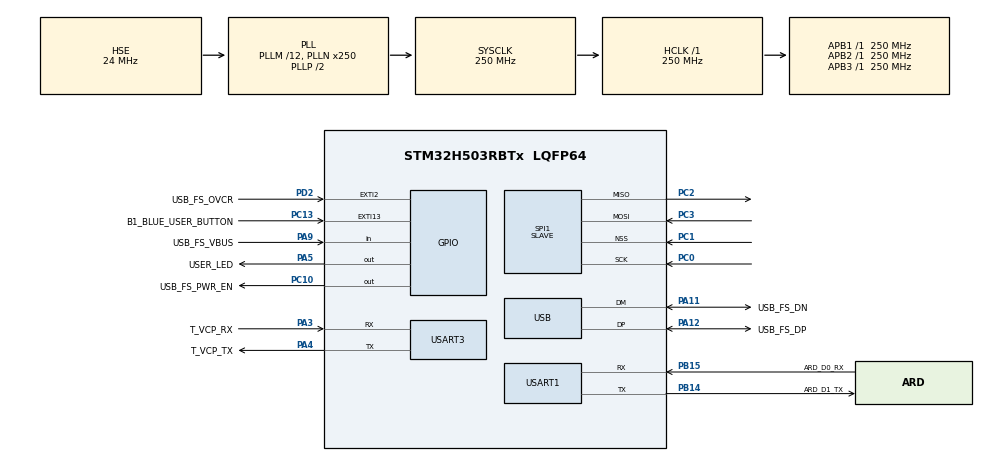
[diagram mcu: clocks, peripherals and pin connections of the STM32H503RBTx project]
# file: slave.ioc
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Mcu.Family=STM32H5
Mcu.Name=STM32H503RBTx
Mcu.Package=LQFP64
NVIC.PriorityGroup=NVIC_PRIORITYGROUP_4
PA11.GPIO_Label=USB_FS_DN
PA11.Mode=Device
PA11.Signal=USB_DM
PA12.GPIO_Label=USB_FS_DP
PA12.Mode=Device
PA12.Signal=USB_DP
PA13(JTMS/SWDIO).GPIO_Label=T_SWDIO
PA13(JTMS/SWDIO).Mode=JTAG_4_pins
PA13(JTMS/SWDIO).Signal=DEBUG_JTMS-SWDIO
PA14(JTCK/SWCLK).GPIO_Label=T_SWCLK
PA14(JTCK/SWCLK).Mode=JTAG_4_pins
PA14(JTCK/SWCLK).Signal=DEBUG_JTCK-SWCLK
PA15(JTDI).GPIO_Label=T_JTDI
PA15(JTDI).Mode=JTAG_4_pins
PA15(JTDI).Signal=DEBUG_JTDI
PA3.GPIO_Label=T_VCP_RX
PA3.Mode=Asynchronous
PA3.Signal=USART3_RX
PA4.GPIO_Label=T_VCP_TX
PA4.Mode=Asynchronous
PA4.Signal=USART3_TX
PA5.GPIO_Label=USER_LED
PA5.Signal=GPIO_Output
PA9.GPIO_Label=USB_FS_VBUS
PA9.Signal=GPIO_Input
PB14.GPIO_Label=ARD_D1_TX
PB14.Mode=Asynchronous
PB14.Signal=USART1_TX
PB15.GPIO_Label=ARD_D0_RX
PB15.Mode=Asynchronous
PB15.Signal=USART1_RX
PB3(JTDO/TRACESWO).GPIO_Label=T_SWO
PB3(JTDO/TRACESWO).Mode=JTAG_4_pins
PB3(JTDO/TRACESWO).Signal=DEBUG_JTDO-SWO
PC0.Mode=Full_Duplex_Slave
PC0.Signal=SPI1_SCK
PC1.Mode=NSS_Signal_Hard_Input
PC1.Signal=SPI1_NSS
PC10.GPIO_Label=USB_FS_PWR_EN
PC10.Signal=GPIO_Output
PC13.GPIO_Label=B1_BLUE_USER_BUTTON
PC13.Signal=GPXTI13
PC14-OSC32_IN(OSC32_IN).Mode=LSE-External-Oscillator
PC14-OSC32_IN(OSC32_IN).Signal=RCC_OSC32_IN
PC15-OSC32_OUT(OSC32_OUT).Mode=LSE-External-Oscillator
PC15-OSC32_OUT(OSC32_OUT).Signal=RCC_OSC32_OUT
PC2.Mode=Full_Duplex_Slave
PC2.Signal=SPI1_MISO
PC3.Mode=Full_Duplex_Slave
PC3.Signal=SPI1_MOSI
PD2.GPIO_Label=USB_FS_OVCR
PD2.Signal=GPXTI2
PH0-OSC_IN(PH0).Mode=HSE-External-Oscillator
PH0-OSC_IN(PH0).Signal=RCC_OSC_IN
PH1-OSC_OUT(PH1).Mode=HSE-External-Oscillator
PH1-OSC_OUT(PH1).Signal=RCC_OSC_OUT
ProjectManager.HeapSize=0x200
ProjectManager.StackSize=0x400
ProjectManager.TargetToolchain=STM32CubeIDE
RCC.ADCFreq_Value=250000000
RCC.AHBFreq_Value=250000000
RCC.APB1Freq_Value=250000000
RCC.APB1TimFreq_Value=250000000
RCC.APB2Freq_Value=250000000
RCC.APB2TimFreq_Value=250000000
RCC.APB3Freq_Value=250000000
RCC.CSI_VALUE=4000000
RCC.CortexFreq_Value=250000000
RCC.EPOD_VALUE=24000000
RCC.HCLKFreq_Value=250000000
RCC.HSE_VALUE=24000000
RCC.HSI48_VALUE=48000000
RCC.HSIDiv=RCC_HSI_DIV1
RCC.HSI_VALUE=64000000
RCC.LSIRC_VALUE=32000
RCC.PLLM=12
RCC.PLLN=250
RCC.PLLSourceVirtual=RCC_PLL1_SOURCE_HSE
RCC.SYSCLKFreq_VALUE=250000000
RCC.SYSCLKSource=RCC_SYSCLKSOURCE_PLLCLK
RCC.USBFreq_Value=48000000
RCC.VCOOutputFreq_Value=500000000
SPI1.DataSize=SPI_DATASIZE_8BIT
SPI1.Direction=SPI_DIRECTION_2LINES
SPI1.Mode=SPI_MODE_SLAVE
SPI1.VirtualNSS=VM_NSSHARD
SPI1.VirtualType=VM_SLAVE
USART1.VirtualMode=VM_ASYNC
USART3.VirtualMode=VM_ASYNC
USB.VirtualMode=Device_Only
VP_BOOTPATH_VS_BOOTPATH.Mode=BP_Activate
VP_ICACHE_VS_ICACHE.Mode=DefaultMode
VP_MEMORYMAP_VS_MEMORYMAP.Mode=CurAppReg
VP_PWR_VS_DBSignals.Mode=DisableDeadBatterySignals
VP_PWR_VS_LPOM.Mode=PowerOptimisation
VP_PWR_VS_SECSignals.Mode=Security/Privilege
board=NUCLEO-H503RB

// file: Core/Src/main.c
/* USER CODE BEGIN Header */
/**
  ******************************************************************************
  * @file           : main.c
  * @brief          : Main program body
  ******************************************************************************
  * @attention
  *
  * Copyright (c) 2024 STMicroelectronics.
  * All rights reserved.
  *
  * This software is licensed under terms that can be found in the LICENSE file
  * in the root directory of this software component.
  * If no LICENSE file comes with this software, it is provided AS-IS.
  *
  ******************************************************************************
  */
/* USER CODE END Header */
#include "main.h"

SPI_HandleTypeDef hspi1;

UART_HandleTypeDef huart1;
UART_HandleTypeDef huart3;

PCD_HandleTypeDef hpcd_USB_DRD_FS;

void SystemClock_Config(void);
static void MX_GPIO_Init(void);
static void MX_ICACHE_Init(void);
static void MX_USART1_UART_Init(void);
static void MX_USART3_UART_Init(void);
static void MX_USB_PCD_Init(void);
static void MX_SPI1_Init(void);

int main(void)
{
  /* USER CODE BEGIN 1 */

	uint8_t expected_data = 0xAA;
	  uint8_t received_data;

  /* USER CODE END 1 */

  /* MCU Configuration--------------------------------------------------------*/

  /* Reset of all peripherals, Initializes the Flash interface and the Systick. */
  HAL_Init();

  /* Configure the system clock */
  SystemClock_Config();

  /* Initialize all configured peripherals */
  MX_GPIO_Init();
  MX_ICACHE_Init();
  MX_USART1_UART_Init();
  MX_USART3_UART_Init();
  MX_USB_PCD_Init();
  MX_SPI1_Init();

  /* Infinite loop */
  /* USER CODE BEGIN WHILE */
	while (1) {

		if (HAL_SPI_Receive(&hspi1, &received_data, 1, HAL_MAX_DELAY)
				== HAL_OK) {
			// Check if received data matches the expected data
			if (received_data == expected_data) {
				for (int i = 0; i < 5; i++) {
					HAL_GPIO_TogglePin(USER_LED_GPIO_Port, USER_LED_Pin);
					HAL_Delay(1000);
				}
				// Data received correctly
				// Add your logic here (e.g., toggle an LED or perform other actions)
				// Example: HAL_GPIO_TogglePin(GPIOB, GPIO_PIN_13); // Toggle LED on GPIOB pin 13
			} else {

				HAL_GPIO_WritePin(USER_LED_GPIO_Port, USER_LED_Pin,
						GPIO_PIN_RESET);
				// Data received incorrectly
				// Add error handling or debugging code here
			}
		}

		HAL_Delay(100); // Adjust delay based on communication frequency
    /* USER CODE END WHILE */

	}
}

void SystemClock_Config(void)
{
  RCC_OscInitTypeDef RCC_OscInitStruct = {0};
  RCC_ClkInitTypeDef RCC_ClkInitStruct = {0};

  /** Configure the main internal regulator output voltage
  */
  __HAL_PWR_VOLTAGESCALING_CONFIG(PWR_REGULATOR_VOLTAGE_SCALE0);

  while(!__HAL_PWR_GET_FLAG(PWR_FLAG_VOSRDY)) {}

  /** Initializes the RCC Oscillators according to the specified parameters
  * in the RCC_OscInitTypeDef structure.
  */
  RCC_OscInitStruct.OscillatorType = RCC_OSCILLATORTYPE_HSI48|RCC_OSCILLATORTYPE_HSE;
  RCC_OscInitStruct.HSEState = RCC_HSE_ON;
  RCC_OscInitStruct.HSI48State = RCC_HSI48_ON;
  RCC_OscInitStruct.PLL.PLLState = RCC_PLL_ON;
  RCC_OscInitStruct.PLL.PLLSource = RCC_PLL1_SOURCE_HSE;
  RCC_OscInitStruct.PLL.PLLM = 12;
  RCC_OscInitStruct.PLL.PLLN = 250;
  RCC_OscInitStruct.PLL.PLLP = 2;
  RCC_OscInitStruct.PLL.PLLQ = 2;
  RCC_OscInitStruct.PLL.PLLR = 2;
  RCC_OscInitStruct.PLL.PLLRGE = RCC_PLL1_VCIRANGE_1;
  RCC_OscInitStruct.PLL.PLLVCOSEL = RCC_PLL1_VCORANGE_WIDE;
  RCC_OscInitStruct.PLL.PLLFRACN = 0;
  if (HAL_RCC_OscConfig(&RCC_OscInitStruct) != HAL_OK)
  {
    Error_Handler();
  }

  /** Initializes the CPU, AHB and APB buses clocks
  */
  RCC_ClkInitStruct.ClockType = RCC_CLOCKTYPE_HCLK|RCC_CLOCKTYPE_SYSCLK
                              |RCC_CLOCKTYPE_PCLK1|RCC_CLOCKTYPE_PCLK2
                              |RCC_CLOCKTYPE_PCLK3;
  RCC_ClkInitStruct.SYSCLKSource = RCC_SYSCLKSOURCE_PLLCLK;
  RCC_ClkInitStruct.AHBCLKDivider = RCC_SYSCLK_DIV1;
  RCC_ClkInitStruct.APB1CLKDivider = RCC_HCLK_DIV1;
  RCC_ClkInitStruct.APB2CLKDivider = RCC_HCLK_DIV1;
  RCC_ClkInitStruct.APB3CLKDivider = RCC_HCLK_DIV1;

  if (HAL_RCC_ClockConfig(&RCC_ClkInitStruct, FLASH_LATENCY_5) != HAL_OK)
  {
    Error_Handler();
  }
}

static void MX_ICACHE_Init(void)
{

  /** Enable instruction cache (default 2-ways set associative cache)
  */
  if (HAL_ICACHE_Enable() != HAL_OK)
  {
    Error_Handler();
  }

}

static void MX_SPI1_Init(void)
{

  /* SPI1 parameter configuration*/
  hspi1.Instance = SPI1;
  hspi1.Init.Mode = SPI_MODE_SLAVE;
  hspi1.Init.Direction = SPI_DIRECTION_2LINES;
  hspi1.Init.DataSize = SPI_DATASIZE_8BIT;
  hspi1.Init.CLKPolarity = SPI_POLARITY_LOW;
  hspi1.Init.CLKPhase = SPI_PHASE_1EDGE;
  hspi1.Init.NSS = SPI_NSS_HARD_INPUT;
  hspi1.Init.FirstBit = SPI_FIRSTBIT_MSB;
  hspi1.Init.TIMode = SPI_TIMODE_DISABLE;
  hspi1.Init.CRCCalculation = SPI_CRCCALCULATION_DISABLE;
  hspi1.Init.CRCPolynomial = 0x7;
  hspi1.Init.NSSPMode = SPI_NSS_PULSE_DISABLE;
  hspi1.Init.NSSPolarity = SPI_NSS_POLARITY_LOW;
  hspi1.Init.FifoThreshold = SPI_FIFO_THRESHOLD_01DATA;
  hspi1.Init.MasterSSIdleness = SPI_MASTER_SS_IDLENESS_00CYCLE;
  hspi1.Init.MasterInterDataIdleness = SPI_MASTER_INTERDATA_IDLENESS_00CYCLE;
  hspi1.Init.MasterReceiverAutoSusp = SPI_MASTER_RX_AUTOSUSP_DISABLE;
  hspi1.Init.MasterKeepIOState = SPI_MASTER_KEEP_IO_STATE_DISABLE;
  hspi1.Init.IOSwap = SPI_IO_SWAP_DISABLE;
  hspi1.Init.ReadyMasterManagement = SPI_RDY_MASTER_MANAGEMENT_INTERNALLY;
  hspi1.Init.ReadyPolarity = SPI_RDY_POLARITY_HIGH;
  if (HAL_SPI_Init(&hspi1) != HAL_OK)
  {
    Error_Handler();
  }

}

static void MX_USART1_UART_Init(void)
{

  huart1.Instance = USART1;
  huart1.Init.BaudRate = 115200;
  huart1.Init.WordLength = UART_WORDLENGTH_8B;
  huart1.Init.StopBits = UART_STOPBITS_1;
  huart1.Init.Parity = UART_PARITY_NONE;
  huart1.Init.Mode = UART_MODE_TX_RX;
  huart1.Init.HwFlowCtl = UART_HWCONTROL_NONE;
  huart1.Init.OverSampling = UART_OVERSAMPLING_16;
  huart1.Init.OneBitSampling = UART_ONE_BIT_SAMPLE_DISABLE;
  huart1.Init.ClockPrescaler = UART_PRESCALER_DIV1;
  huart1.AdvancedInit.AdvFeatureInit = UART_ADVFEATURE_NO_INIT;
  if (HAL_UART_Init(&huart1) != HAL_OK)
  {
    Error_Handler();
  }
  if (HAL_UARTEx_SetTxFifoThreshold(&huart1, UART_TXFIFO_THRESHOLD_1_8) != HAL_OK)
  {
    Error_Handler();
  }
  if (HAL_UARTEx_SetRxFifoThreshold(&huart1, UART_RXFIFO_THRESHOLD_1_8) != HAL_OK)
  {
    Error_Handler();
  }
  if (HAL_UARTEx_DisableFifoMode(&huart1) != HAL_OK)
  {
    Error_Handler();
  }

}

static void MX_USART3_UART_Init(void)
{

  huart3.Instance = USART3;
  huart3.Init.BaudRate = 115200;
  huart3.Init.WordLength = UART_WORDLENGTH_8B;
  huart3.Init.StopBits = UART_STOPBITS_1;
  huart3.Init.Parity = UART_PARITY_NONE;
  huart3.Init.Mode = UART_MODE_TX_RX;
  huart3.Init.HwFlowCtl = UART_HWCONTROL_NONE;
  huart3.Init.OverSampling = UART_OVERSAMPLING_16;
  huart3.Init.OneBitSampling = UART_ONE_BIT_SAMPLE_DISABLE;
  huart3.Init.ClockPrescaler = UART_PRESCALER_DIV1;
  huart3.AdvancedInit.AdvFeatureInit = UART_ADVFEATURE_NO_INIT;
  if (HAL_UART_Init(&huart3) != HAL_OK)
  {
    Error_Handler();
  }
  if (HAL_UARTEx_SetTxFifoThreshold(&huart3, UART_TXFIFO_THRESHOLD_1_8) != HAL_OK)
  {
    Error_Handler();
  }
  if (HAL_UARTEx_SetRxFifoThreshold(&huart3, UART_RXFIFO_THRESHOLD_1_8) != HAL_OK)
  {
    Error_Handler();
  }
  if (HAL_UARTEx_DisableFifoMode(&huart3) != HAL_OK)
  {
    Error_Handler();
  }

}

static void MX_USB_PCD_Init(void)
{

  hpcd_USB_DRD_FS.Instance = USB_DRD_FS;
  hpcd_USB_DRD_FS.Init.dev_endpoints = 8;
  hpcd_USB_DRD_FS.Init.speed = USBD_FS_SPEED;
  hpcd_USB_DRD_FS.Init.phy_itface = PCD_PHY_EMBEDDED;
  hpcd_USB_DRD_FS.Init.Sof_enable = DISABLE;
  hpcd_USB_DRD_FS.Init.low_power_enable = DISABLE;
  hpcd_USB_DRD_FS.Init.lpm_enable = DISABLE;
  hpcd_USB_DRD_FS.Init.battery_charging_enable = DISABLE;
  hpcd_USB_DRD_FS.Init.vbus_sensing_enable = DISABLE;
  hpcd_USB_DRD_FS.Init.bulk_doublebuffer_enable = DISABLE;
  hpcd_USB_DRD_FS.Init.iso_singlebuffer_enable = DISABLE;
  if (HAL_PCD_Init(&hpcd_USB_DRD_FS) != HAL_OK)
  {
    Error_Handler();
  }

}

static void MX_GPIO_Init(void)
{
  GPIO_InitTypeDef GPIO_InitStruct = {0};

  /* GPIO Ports Clock Enable */
  __HAL_RCC_GPIOC_CLK_ENABLE();
  __HAL_RCC_GPIOH_CLK_ENABLE();
  __HAL_RCC_GPIOA_CLK_ENABLE();
  __HAL_RCC_GPIOB_CLK_ENABLE();
  __HAL_RCC_GPIOD_CLK_ENABLE();

  /*Configure GPIO pin Output Level */
  HAL_GPIO_WritePin(USER_LED_GPIO_Port, USER_LED_Pin, GPIO_PIN_RESET);

  /*Configure GPIO pin Output Level */
  HAL_GPIO_WritePin(USB_FS_PWR_EN_GPIO_Port, USB_FS_PWR_EN_Pin, GPIO_PIN_RESET);

  /*Configure GPIO pin : B1_BLUE_USER_BUTTON_Pin */
  GPIO_InitStruct.Pin = B1_BLUE_USER_BUTTON_Pin;
  GPIO_InitStruct.Mode = GPIO_MODE_IT_RISING;
  GPIO_InitStruct.Pull = GPIO_NOPULL;
  HAL_GPIO_Init(B1_BLUE_USER_BUTTON_GPIO_Port, &GPIO_InitStruct);

  /*Configure GPIO pin : USER_LED_Pin */
  GPIO_InitStruct.Pin = USER_LED_Pin;
  GPIO_InitStruct.Mode = GPIO_MODE_OUTPUT_PP;
  GPIO_InitStruct.Pull = GPIO_NOPULL;
  GPIO_InitStruct.Speed = GPIO_SPEED_FREQ_LOW;
  HAL_GPIO_Init(USER_LED_GPIO_Port, &GPIO_InitStruct);

  /*Configure GPIO pin : USB_FS_VBUS_Pin */
  GPIO_InitStruct.Pin = USB_FS_VBUS_Pin;
  GPIO_InitStruct.Mode = GPIO_MODE_INPUT;
  GPIO_InitStruct.Pull = GPIO_NOPULL;
  HAL_GPIO_Init(USB_FS_VBUS_GPIO_Port, &GPIO_InitStruct);

  /*Configure GPIO pin : USB_FS_PWR_EN_Pin */
  GPIO_InitStruct.Pin = USB_FS_PWR_EN_Pin;
  GPIO_InitStruct.Mode = GPIO_MODE_OUTPUT_PP;
  GPIO_InitStruct.Pull = GPIO_NOPULL;
  GPIO_InitStruct.Speed = GPIO_SPEED_FREQ_LOW;
  HAL_GPIO_Init(USB_FS_PWR_EN_GPIO_Port, &GPIO_InitStruct);

  /*Configure GPIO pin : USB_FS_OVCR_Pin */
  GPIO_InitStruct.Pin = USB_FS_OVCR_Pin;
  GPIO_InitStruct.Mode = GPIO_MODE_IT_RISING;
  GPIO_InitStruct.Pull = GPIO_NOPULL;
  HAL_GPIO_Init(USB_FS_OVCR_GPIO_Port, &GPIO_InitStruct);

}

void Error_Handler(void)
{
  __disable_irq();
  while (1)
  {
  }
}
